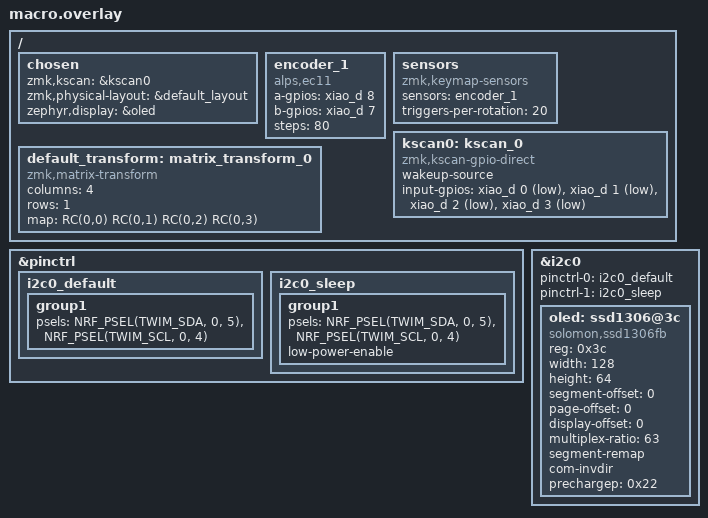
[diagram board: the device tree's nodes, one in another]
#include <dt-bindings/zmk/matrix_transform.h>
#include <dt-bindings/pinctrl/nrf-pinctrl.h> // <-- Add this include for NRF_PSEL
#include "macro-layouts.dtsi"

// 1. Remap the I2C pins (D5 = SDA, D4 = SCL)
&pinctrl {
    i2c0_default: i2c0_default {
        group1 {
            psels = <NRF_PSEL(TWIM_SDA, 0, 5)>, // D5 (P0.05) as SDA
                    <NRF_PSEL(TWIM_SCL, 0, 4)>; // D4 (P0.04) as SCL
        };
    };

    i2c0_sleep: i2c0_sleep {
        group1 {
            psels = <NRF_PSEL(TWIM_SDA, 0, 5)>,
                    <NRF_PSEL(TWIM_SCL, 0, 4)>;
            low-power-enable;
        };
    };
};

// 2. Setup the OLED Display on the remapped pins
&i2c0 {
    status = "okay";
    pinctrl-0 = <&i2c0_default>;
    pinctrl-1 = <&i2c0_sleep>;
    pinctrl-names = "default", "sleep";

    oled: ssd1306@3c {
        compatible = "solomon,ssd1306fb";
        reg = <0x3c>;
        width = <128>;
        height = <64>;
        segment-offset = <0>;
        page-offset = <0>;
        display-offset = <0>;
        multiplex-ratio = <63>;
        segment-remap;
        com-invdir;
        prechargep = <0x22>;
    };
};

/ {
    chosen {
        zmk,kscan = &kscan0;
        zmk,physical-layout = &default_layout;
        zephyr,display = &oled;
    };
    // 2. Define the Rotary Encoder
    // MOVED to D3 and D7 to prevent crashing the I2C display!
    encoder_1: encoder_1 {
        compatible = "alps,ec11";
        a-gpios = <&xiao_d 8 (GPIO_ACTIVE_HIGH | GPIO_PULL_UP)>;
        b-gpios = <&xiao_d 7 (GPIO_ACTIVE_HIGH | GPIO_PULL_UP)>; // Moved to D7
        steps = <80>;
        status = "okay";
    };

    sensors {
        compatible = "zmk,keymap-sensors";
        sensors = <&encoder_1>;
        triggers-per-rotation = <20>; 
    };

    // 3. Define Direct GPIO for your 4 buttons
    kscan0: kscan_0 {
        compatible = "zmk,kscan-gpio-direct";
        wakeup-source;
        input-gpios
            = <&xiao_d 0 (GPIO_ACTIVE_LOW | GPIO_PULL_UP)>  // B1
            , <&xiao_d 1 (GPIO_ACTIVE_LOW | GPIO_PULL_UP)>  // B2
            , <&xiao_d 2 (GPIO_ACTIVE_LOW | GPIO_PULL_UP)>  // B3
            , <&xiao_d 3 (GPIO_ACTIVE_LOW | GPIO_PULL_UP)>  // Encoder Button (Moved to D8)
            ;
    };

    // 4. Map the 4 keys in a single straight line
    default_transform: matrix_transform_0 {
        compatible = "zmk,matrix-transform";
        columns = <4>;
        rows = <1>;
        map = <
            RC(0,0) RC(0,1) RC(0,2) RC(0,3)
        >;
    };
};
